# HDSC_HC32F472 register map
Vendor: HDSC; Series: ARMCM4; File version: 1.0
CPU: CM4 r0p1, little endian, MPU, FPU, 4 interrupt priority bits
Registers are 32-bit, read-write, reset 0x0 unless marked. A register's access mark holds for its fields unless they carry their own. Offsets are from the block's base; [hi:lo] are bit positions; {n}, {i} and the like mark numbered series.

## KEYSCAN
Base 0x40050C00
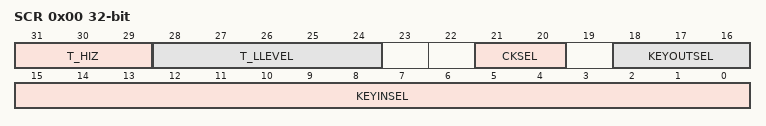
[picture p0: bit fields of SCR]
0x00 SCR
  [31:29] T_HIZ, [28:24] T_LLEVEL, [21:20] CKSEL, [18:16] KEYOUTSEL, [15:0] KEYINSEL
0x04 SER
  [0] SEN
0x08 SSR
  [2:0] INDEX

## MAU
Base 0x40055000
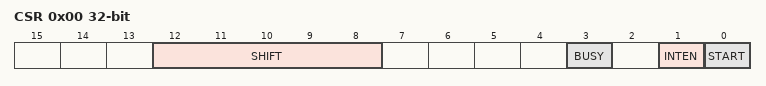
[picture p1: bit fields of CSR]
0x00 CSR
  [12:8] SHIFT, [3] BUSY, [1] INTEN, [0] START
0x04 DTR0
0x0C RTR0
  [16:0] SQRT_DOUT
0x10 DTR1
  [11:0] SIN_DIN
0x14 RTR1
  [15:0] SIN_DOUT

## MDIO
Base 0x40028400
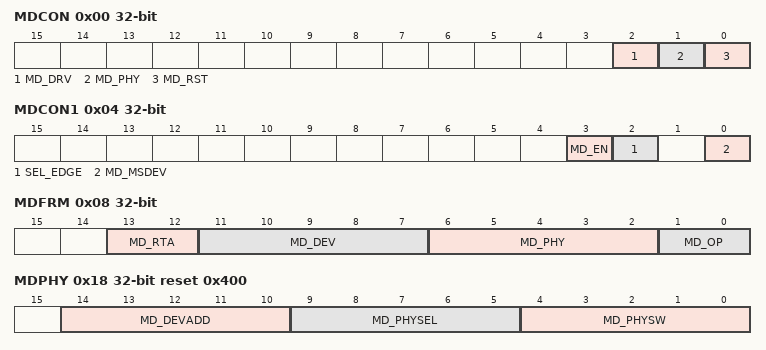
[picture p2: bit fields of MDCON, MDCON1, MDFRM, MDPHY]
0x00 MDCON
  [2] MD_DRV, [1] MD_PHY, [0] MD_RST
0x04 MDCON1
  [3] MD_EN, [2] SEL_EDGE, [0] MD_MSDEV
0x08 MDFRM ro
  [13:12] MD_RTA, [11:7] MD_DEV, [6:2] MD_PHY, [1:0] MD_OP
0x0C MDRXD ro
  [15:0] MD_RXD
0x10 MDADR ro
  [15:0] MD_ADR
0x14 MDTXD
  [15:0] MD_TXD
0x18 MDPHY reset 0x400
  [14:10] MD_DEVADD, [9:5] MD_PHYSEL, [4:0] MD_PHYSW
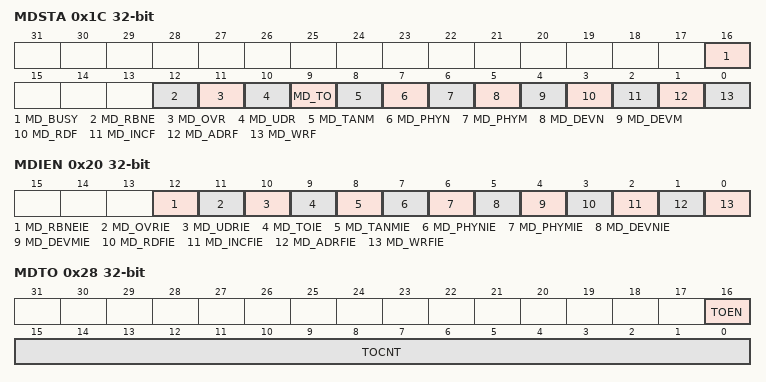
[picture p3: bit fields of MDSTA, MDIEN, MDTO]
0x1C MDSTA
  [16] MD_BUSY, [12] MD_RBNE, [11] MD_OVR, [10] MD_UDR, [9] MD_TO, [8] MD_TANM, [7] MD_PHYN, [6] MD_PHYM, [5] MD_DEVN, [4] MD_DEVM, [3] MD_RDF, [2] MD_INCF, [1] MD_ADRF, [0] MD_WRF
0x20 MDIEN
  [12] MD_RBNEIE, [11] MD_OVRIE, [10] MD_UDRIE, [9] MD_TOIE, [8] MD_TANMIE, [7] MD_PHYNIE, [6] MD_PHYMIE, [5] MD_DEVNIE, [4] MD_DEVMIE, [3] MD_RDFIE, [2] MD_INCFIE, [1] MD_ADRFIE, [0] MD_WRFIE
0x24 MDPIN ro
  [4:0] MD_PIN
0x28 MDTO
  [16] TOEN, [15:0] TOCNT

## MPU
Base 0x40050000
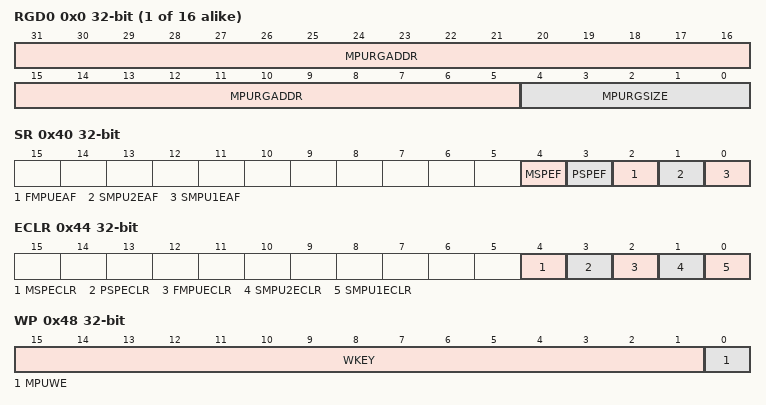
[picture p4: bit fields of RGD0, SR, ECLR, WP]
{0x0+4i} RGD{i} (i=0..15)
  [31:5] MPURGADDR, [4:0] MPURGSIZE
0x40 SR ro
  [4] MSPEF, [3] PSPEF, [2] FMPUEAF, [1] SMPU2EAF, [0] SMPU1EAF
0x44 ECLR wo
  [4] MSPECLR, [3] PSPECLR, [2] FMPUECLR, [1] SMPU2ECLR, [0] SMPU1ECLR
0x48 WP
  [15:1] WKEY, [0] MPUWE
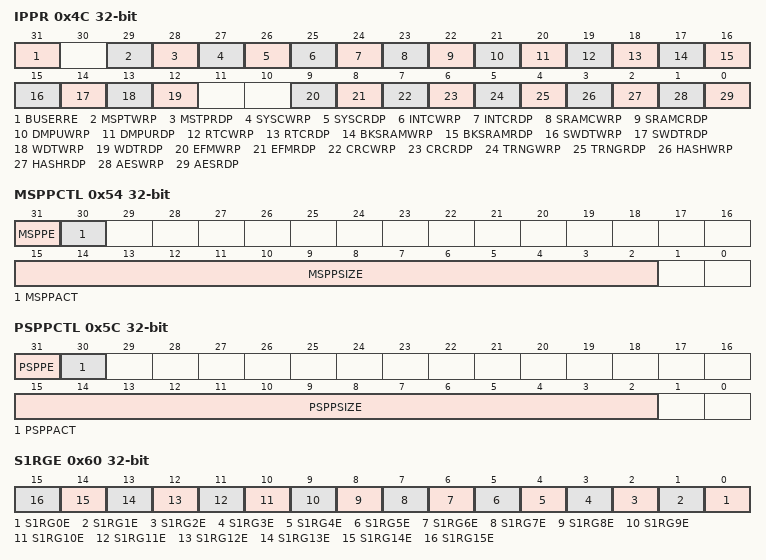
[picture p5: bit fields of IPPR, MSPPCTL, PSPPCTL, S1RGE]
0x4C IPPR
  [31] BUSERRE, [29] MSPTWRP, [28] MSTPRDP, [27] SYSCWRP, [26] SYSCRDP, [25] INTCWRP, [24] INTCRDP, [23] SRAMCWRP, [22] SRAMCRDP, [21] DMPUWRP, [20] DMPURDP, [19] RTCWRP, [18] RTCRDP, [17] BKSRAMWRP, [16] BKSRAMRDP, [15] SWDTWRP, [14] SWDTRDP, [13] WDTWRP, [12] WDTRDP, [9] EFMWRP, [8] EFMRDP, [7] CRCWRP, [6] CRCRDP, [5] TRNGWRP, [4] TRNGRDP, [3] HASHWRP, [2] HASHRDP, [1] AESWRP, [0] AESRDP
0x50 MSPPBA
  [31:2] MSPPBA
0x54 MSPPCTL
  [31] MSPPE, [30] MSPPACT, [15:2] MSPPSIZE
0x58 PSPPBA
  [31:2] PSPPBA
0x5C PSPPCTL
  [31] PSPPE, [30] PSPPACT, [15:2] PSPPSIZE
0x60 S1RGE
  [n] S1RG{n}E (n=0..15)
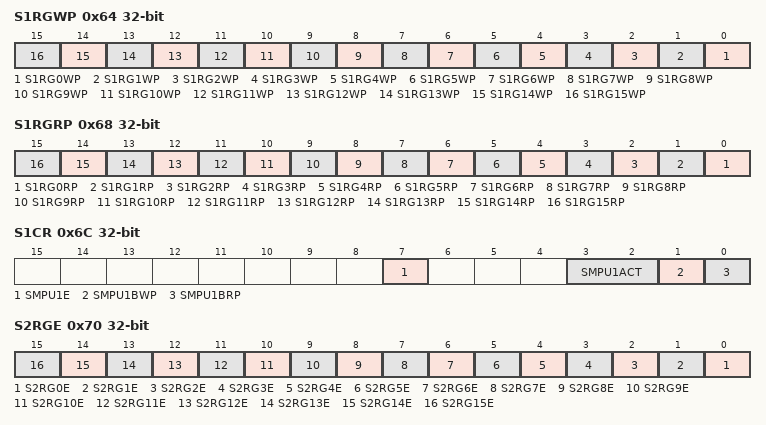
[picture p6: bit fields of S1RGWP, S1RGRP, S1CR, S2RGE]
0x64 S1RGWP
  [n] S1RG{n}WP (n=0..15)
0x68 S1RGRP
  [n] S1RG{n}RP (n=0..15)
0x6C S1CR
  [7] SMPU1E, [3:2] SMPU1ACT, [1] SMPU1BWP, [0] SMPU1BRP
0x70 S2RGE
  [n] S2RG{n}E (n=0..15)
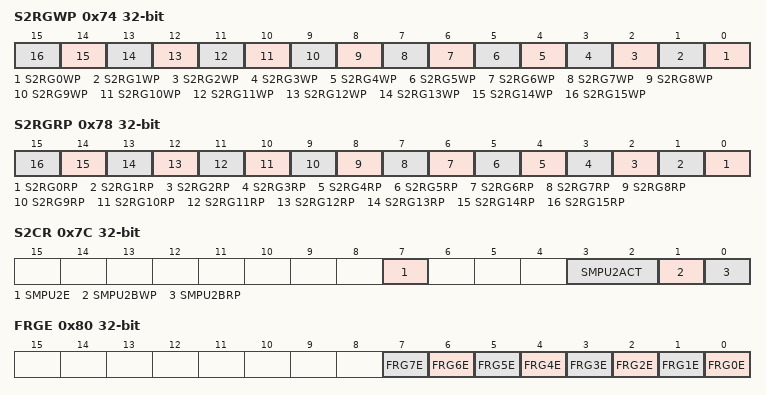
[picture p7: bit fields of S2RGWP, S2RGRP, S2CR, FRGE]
0x74 S2RGWP
  [n] S2RG{n}WP (n=0..15)
0x78 S2RGRP
  [n] S2RG{n}RP (n=0..15)
0x7C S2CR
  [7] SMPU2E, [3:2] SMPU2ACT, [1] SMPU2BWP, [0] SMPU2BRP
0x80 FRGE
  [n] FRG{n}E (n=0..7)
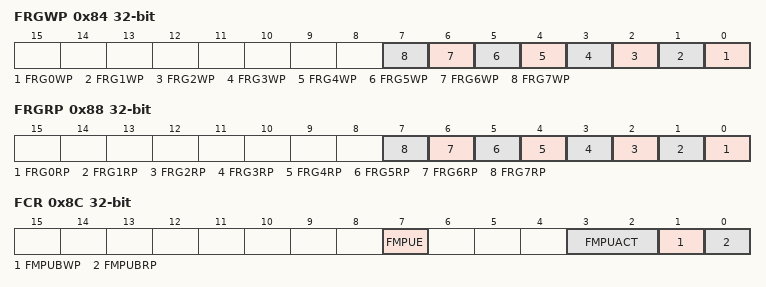
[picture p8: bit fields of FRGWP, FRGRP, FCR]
0x84 FRGWP
  [n] FRG{n}WP (n=0..7)
0x88 FRGRP
  [n] FRG{n}RP (n=0..7)
0x8C FCR
  [7] FMPUE, [3:2] FMPUACT, [1] FMPUBWP, [0] FMPUBRP

## OTS
Base 0x40010600
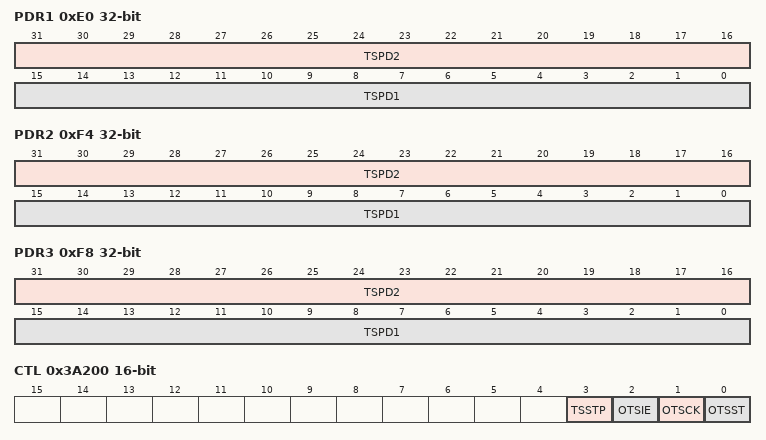
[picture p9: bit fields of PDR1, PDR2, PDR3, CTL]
0xE0 PDR1
  [31:16] TSPD2, [15:0] TSPD1
0xF4 PDR2
  [31:16] TSPD2, [15:0] TSPD1
0xF8 PDR3
  [31:16] TSPD2, [15:0] TSPD1
0x3A200 CTL 16-bit
  [3] TSSTP, [2] OTSIE, [1] OTSCK, [0] OTSST
0x3A202 DR1 16-bit
0x3A204 DR2 16-bit
0x3A206 ECR 16-bit
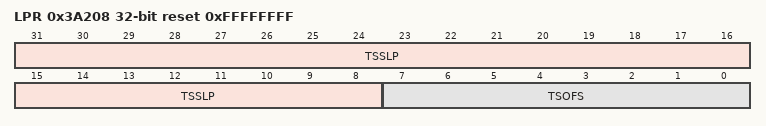
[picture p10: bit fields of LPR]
0x3A208 LPR ro reset 0xFFFFFFFF
  [31:8] TSSLP, [7:0] TSOFS

## PERIC
Base 0x40055400
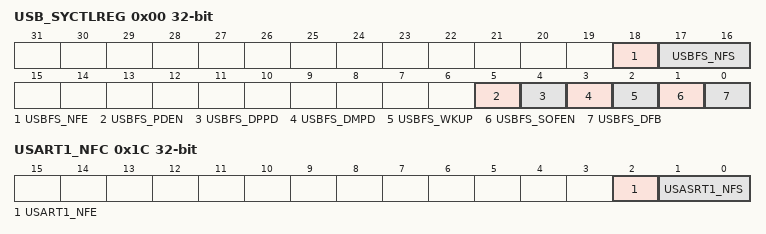
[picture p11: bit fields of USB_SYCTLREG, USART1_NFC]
0x00 USB_SYCTLREG
  [18] USBFS_NFE, [17:16] USBFS_NFS, [5] USBFS_PDEN, [4] USBFS_DPPD, [3] USBFS_DMPD, [2] USBFS_WKUP, [1] USBFS_SOFEN, [0] USBFS_DFB
0x0C SMC_ENAR
  [1] SMCEN
0x1C USART1_NFC
  [2] USART1_NFE, [1:0] USASRT1_NFS

## PLA
Base 0x40028000
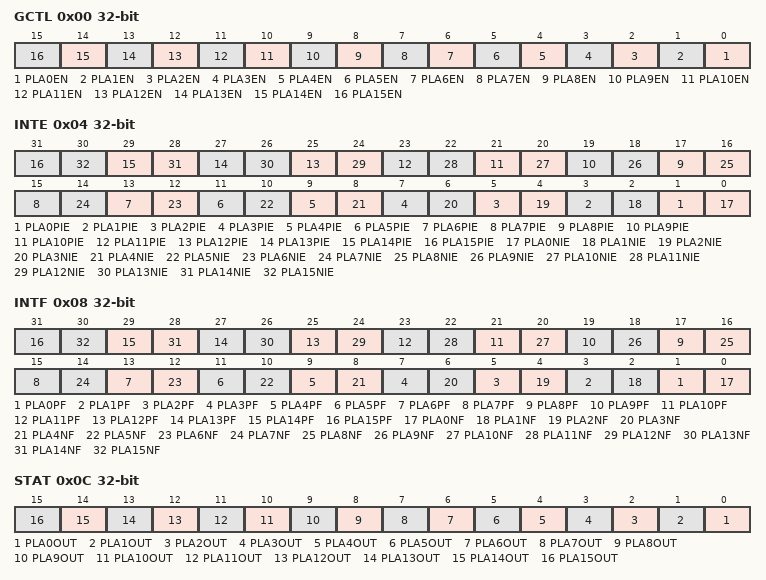
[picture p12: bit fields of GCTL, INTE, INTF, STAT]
0x00 GCTL
  [n] PLA{n}EN (n=0..15)
0x04 INTE
  [2n+1] PLA{n}PIE (n=0..15), [2n] PLA{n}NIE (n=0..15)
0x08 INTF
  [2n+1] PLA{n}PF (n=0..15), [2n] PLA{n}NF (n=0..15)
0x0C STAT ro
  [n] PLA{n}OUT (n=0..15)
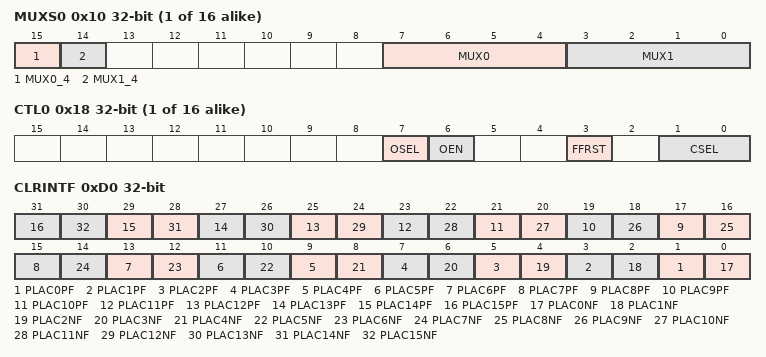
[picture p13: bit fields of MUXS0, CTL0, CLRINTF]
{0x10+0xC*i} MUXS{i} (i=0..15)
  [15] MUX0_4, [14] MUX1_4, [7:4] MUX0, [3:0] MUX1
{0x14+0xC*i} LUTCTL{i} (i=0..15)
  [7:0] LUTCTL
{0x18+0xC*i} CTL{i} (i=0..15)
  [7] OSEL, [6] OEN, [3] FFRST, [1:0] CSEL
0xD0 CLRINTF wo
  [2n+1] PLAC{n}PF (n=0..15), [2n] PLAC{n}NF (n=0..15)
